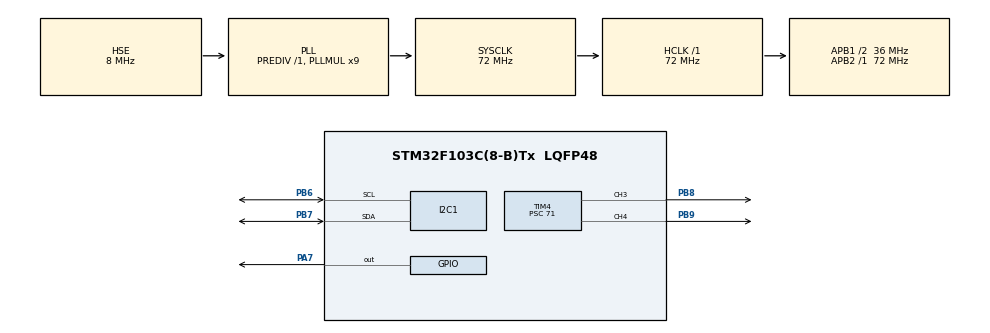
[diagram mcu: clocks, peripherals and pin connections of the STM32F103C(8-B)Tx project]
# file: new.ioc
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Mcu.Family=STM32F1
Mcu.Name=STM32F103C(8-B)Tx
Mcu.Package=LQFP48
NVIC.PriorityGroup=NVIC_PRIORITYGROUP_4
PA13.Mode=Serial_Wire
PA13.Signal=SYS_JTMS-SWDIO
PA14.Mode=Serial_Wire
PA14.Signal=SYS_JTCK-SWCLK
PA7.PinState=GPIO_PIN_SET
PA7.Signal=GPIO_Output
PB6.Mode=I2C
PB6.Signal=I2C1_SCL
PB7.Mode=I2C
PB7.Signal=I2C1_SDA
PB8.Signal=S_TIM4_CH3
PB9.Signal=S_TIM4_CH4
PC14-OSC32_IN.Mode=LSE-External-Oscillator
PC14-OSC32_IN.Signal=RCC_OSC32_IN
PC15-OSC32_OUT.Mode=LSE-External-Oscillator
PC15-OSC32_OUT.Signal=RCC_OSC32_OUT
PD0-OSC_IN.Mode=HSE-External-Oscillator
PD0-OSC_IN.Signal=RCC_OSC_IN
PD1-OSC_OUT.Mode=HSE-External-Oscillator
PD1-OSC_OUT.Signal=RCC_OSC_OUT
ProjectManager.HeapSize=0x200
ProjectManager.StackSize=0x400
ProjectManager.TargetToolchain=MDK-ARM V5.32
RCC.AHBFreq_Value=72000000
RCC.APB1CLKDivider=RCC_HCLK_DIV2
RCC.APB1Freq_Value=36000000
RCC.APB1TimFreq_Value=72000000
RCC.APB2Freq_Value=72000000
RCC.APB2TimFreq_Value=72000000
RCC.HCLKFreq_Value=72000000
RCC.PLLMUL=RCC_PLL_MUL9
RCC.PLLSourceVirtual=RCC_PLLSOURCE_HSE
RCC.SYSCLKFreq_VALUE=72000000
RCC.SYSCLKSource=RCC_SYSCLKSOURCE_PLLCLK
RCC.USBFreq_Value=72000000
SH.S_TIM4_CH3.0=TIM4_CH3,PWM Generation3 CH3
SH.S_TIM4_CH4.0=TIM4_CH4,PWM Generation4 CH4
TIM4.AutoReloadPreload=TIM_AUTORELOAD_PRELOAD_DISABLE
TIM4.Channel-PWM\ Generation1\ CH1=TIM_CHANNEL_1
TIM4.Channel-PWM\ Generation2\ CH2=TIM_CHANNEL_2
TIM4.Channel-PWM\ Generation3\ CH3=TIM_CHANNEL_3
TIM4.Channel-PWM\ Generation4\ CH4=TIM_CHANNEL_4
TIM4.ClockDivision=TIM_CLOCKDIVISION_DIV1
TIM4.Period=19999
TIM4.Prescaler=71
TIM4.Pulse-PWM\ Generation1\ CH1=500
VP_TIM4_VS_ClockSourceINT.Mode=Internal
board=custom

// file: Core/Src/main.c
/* USER CODE BEGIN Header */
/**
  ******************************************************************************
  * @file           : main.c
  * @brief          : Main program body
  ******************************************************************************
  * @attention
  *
  * Copyright (c) 2026 STMicroelectronics.
  * All rights reserved.
  *
  * This software is licensed under terms that can be found in the LICENSE file
  * in the root directory of this software component.
  * If no LICENSE file comes with this software, it is provided AS-IS.
  *
  ******************************************************************************
  */
/* USER CODE END Header */
#include "main.h"

/* USER CODE BEGIN Includes */
#include "../../icode/oled/oled.h"
/* USER CODE END Includes */

I2C_HandleTypeDef hi2c1;

TIM_HandleTypeDef htim4;

void SystemClock_Config(void);
static void MX_GPIO_Init(void);
static void MX_TIM4_Init(void);
static void MX_I2C1_Init(void);

int main(void)
{

  /* MCU Configuration--------------------------------------------------------*/

  /* Reset of all peripherals, Initializes the Flash interface and the Systick. */
  HAL_Init();

  /* Configure the system clock */
  SystemClock_Config();

  /* Initialize all configured peripherals */
  MX_GPIO_Init();
  MX_TIM4_Init();
  MX_I2C1_Init();
  /* USER CODE BEGIN 2 */
  HAL_TIM_PWM_Start(&htim4, TIM_CHANNEL_1);
  OLED_Init();                           //OLED初始
   OLED_Clear();                         //清屏
  //上面的初始化以及清屏的代码在一开始处一定要写
//   OLED_ShowString(0,0,"UNICORN_LI",16, 1);    //反相显示8X16字符串
//   OLED_ShowString(0,2,"unicorn_li_123",12,0);//正相显示6X8字符串
//
//   OLED_ShowCHinese(0,6,0,0); //正相显示汉字“独”
//   OLED_ShowCHinese(16,6,1,0);//正相显示汉字“角”
//   OLED_ShowCHinese(32,6,2,0);//正相显示汉字“兽”
//
//   OLED_ShowNum(48,4,6,1,16, 0);//正相显示1位8X16数字“6”
//   OLED_ShowNum(48,7,77,2,12, 1);//反相显示2位6X8数字“77”
//   OLED_DrawBMP(90,0,122, 4,BMP1,0);//正相显示图片BMP1
   OLED_DrawBMP(0,0,128,6,BMP4,0);
//   OLED_ShowCHinese(50,6,3,0);//正相显示汉字“前”
//   OLED_ShowCHinese(66,6,4,0);//正相显示汉字“进”
//	OLED_ShowCHinese(44,6,5,0);//正相显示汉字“伸”
//	OLED_ShowCHinese(60,6,6,0);//正相显示汉字“懒”
//	OLED_ShowCHinese(76,6,7,0);//正相显示汉字“腰”
	OLED_ShowCHinese(44,6,8,0);//正相显示汉字“打”
	OLED_ShowCHinese(60,6,9,0);//正相显示汉字“招”
	OLED_ShowCHinese(76,6,10,0);//正相显示汉字“呼”

//   OLED_HorizontalShift(0x26);//全屏水平向右滚动播放

  /* USER CODE END 2 */

  /* Infinite loop */
  while (1)
  {

  }
}

void SystemClock_Config(void)
{
  RCC_OscInitTypeDef RCC_OscInitStruct = {0};
  RCC_ClkInitTypeDef RCC_ClkInitStruct = {0};

  /** Initializes the RCC Oscillators according to the specified parameters
  * in the RCC_OscInitTypeDef structure.
  */
  RCC_OscInitStruct.OscillatorType = RCC_OSCILLATORTYPE_HSE;
  RCC_OscInitStruct.HSEState = RCC_HSE_ON;
  RCC_OscInitStruct.HSEPredivValue = RCC_HSE_PREDIV_DIV1;
  RCC_OscInitStruct.HSIState = RCC_HSI_ON;
  RCC_OscInitStruct.PLL.PLLState = RCC_PLL_ON;
  RCC_OscInitStruct.PLL.PLLSource = RCC_PLLSOURCE_HSE;
  RCC_OscInitStruct.PLL.PLLMUL = RCC_PLL_MUL9;
  if (HAL_RCC_OscConfig(&RCC_OscInitStruct) != HAL_OK)
  {
    Error_Handler();
  }

  /** Initializes the CPU, AHB and APB buses clocks
  */
  RCC_ClkInitStruct.ClockType = RCC_CLOCKTYPE_HCLK|RCC_CLOCKTYPE_SYSCLK
                              |RCC_CLOCKTYPE_PCLK1|RCC_CLOCKTYPE_PCLK2;
  RCC_ClkInitStruct.SYSCLKSource = RCC_SYSCLKSOURCE_PLLCLK;
  RCC_ClkInitStruct.AHBCLKDivider = RCC_SYSCLK_DIV1;
  RCC_ClkInitStruct.APB1CLKDivider = RCC_HCLK_DIV2;
  RCC_ClkInitStruct.APB2CLKDivider = RCC_HCLK_DIV1;

  if (HAL_RCC_ClockConfig(&RCC_ClkInitStruct, FLASH_LATENCY_2) != HAL_OK)
  {
    Error_Handler();
  }
}

static void MX_I2C1_Init(void)
{

  hi2c1.Instance = I2C1;
  hi2c1.Init.ClockSpeed = 100000;
  hi2c1.Init.DutyCycle = I2C_DUTYCYCLE_2;
  hi2c1.Init.OwnAddress1 = 0;
  hi2c1.Init.AddressingMode = I2C_ADDRESSINGMODE_7BIT;
  hi2c1.Init.DualAddressMode = I2C_DUALADDRESS_DISABLE;
  hi2c1.Init.OwnAddress2 = 0;
  hi2c1.Init.GeneralCallMode = I2C_GENERALCALL_DISABLE;
  hi2c1.Init.NoStretchMode = I2C_NOSTRETCH_DISABLE;
  if (HAL_I2C_Init(&hi2c1) != HAL_OK)
  {
    Error_Handler();
  }

}

static void MX_TIM4_Init(void)
{

  TIM_ClockConfigTypeDef sClockSourceConfig = {0};
  TIM_MasterConfigTypeDef sMasterConfig = {0};
  TIM_OC_InitTypeDef sConfigOC = {0};

  htim4.Instance = TIM4;
  htim4.Init.Prescaler = 71;
  htim4.Init.CounterMode = TIM_COUNTERMODE_UP;
  htim4.Init.Period = 19999;
  htim4.Init.ClockDivision = TIM_CLOCKDIVISION_DIV1;
  htim4.Init.AutoReloadPreload = TIM_AUTORELOAD_PRELOAD_DISABLE;
  if (HAL_TIM_Base_Init(&htim4) != HAL_OK)
  {
    Error_Handler();
  }
  sClockSourceConfig.ClockSource = TIM_CLOCKSOURCE_INTERNAL;
  if (HAL_TIM_ConfigClockSource(&htim4, &sClockSourceConfig) != HAL_OK)
  {
    Error_Handler();
  }
  if (HAL_TIM_PWM_Init(&htim4) != HAL_OK)
  {
    Error_Handler();
  }
  sMasterConfig.MasterOutputTrigger = TIM_TRGO_RESET;
  sMasterConfig.MasterSlaveMode = TIM_MASTERSLAVEMODE_DISABLE;
  if (HAL_TIMEx_MasterConfigSynchronization(&htim4, &sMasterConfig) != HAL_OK)
  {
    Error_Handler();
  }
  sConfigOC.OCMode = TIM_OCMODE_PWM1;
  sConfigOC.Pulse = 0;
  sConfigOC.OCPolarity = TIM_OCPOLARITY_HIGH;
  sConfigOC.OCFastMode = TIM_OCFAST_DISABLE;
  if (HAL_TIM_PWM_ConfigChannel(&htim4, &sConfigOC, TIM_CHANNEL_3) != HAL_OK)
  {
    Error_Handler();
  }
  if (HAL_TIM_PWM_ConfigChannel(&htim4, &sConfigOC, TIM_CHANNEL_4) != HAL_OK)
  {
    Error_Handler();
  }
  HAL_TIM_MspPostInit(&htim4);

}

static void MX_GPIO_Init(void)
{
  GPIO_InitTypeDef GPIO_InitStruct = {0};

  /* GPIO Ports Clock Enable */
  __HAL_RCC_GPIOC_CLK_ENABLE();
  __HAL_RCC_GPIOD_CLK_ENABLE();
  __HAL_RCC_GPIOA_CLK_ENABLE();
  __HAL_RCC_GPIOB_CLK_ENABLE();

  /*Configure GPIO pin Output Level */
  HAL_GPIO_WritePin(GPIOA, GPIO_PIN_7, GPIO_PIN_SET);

  /*Configure GPIO pin : PA7 */
  GPIO_InitStruct.Pin = GPIO_PIN_7;
  GPIO_InitStruct.Mode = GPIO_MODE_OUTPUT_PP;
  GPIO_InitStruct.Pull = GPIO_NOPULL;
  GPIO_InitStruct.Speed = GPIO_SPEED_FREQ_LOW;
  HAL_GPIO_Init(GPIOA, &GPIO_InitStruct);

}

void Error_Handler(void)
{
  __disable_irq();
  while (1)
  {
  }
}
